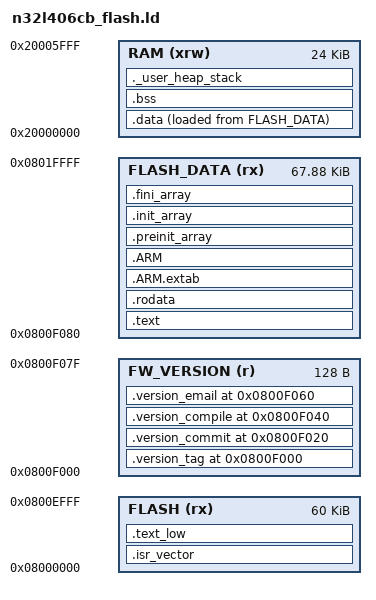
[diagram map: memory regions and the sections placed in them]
/**
  ****************************************************************************
  Copyright (c) 2019, Nations Technologies Inc.

  All rights reserved.
  ****************************************************************************

  Redistribution and use in source and binary forms, with or without
  modification, are permitted provided that the following conditions are met:

  - Redistributions of source code must retain the above copyright notice,
  this list of conditions and the disclaimer below.

  Nations' name may not be used to endorse or promote products derived from
  this software without specific prior written permission.

  DISCLAIMER: THIS SOFTWARE IS PROVIDED BY NATIONS "AS IS" AND ANY EXPRESS OR
  IMPLIED WARRANTIES, INCLUDING, BUT NOT LIMITED TO, THE IMPLIED WARRANTIES OF
  MERCHANTABILITY, FITNESS FOR A PARTICULAR PURPOSE AND NON-INFRINGEMENT ARE
  DISCLAIMED. IN NO EVENT SHALL NATIONS BE LIABLE FOR ANY DIRECT, INDIRECT,
  INCIDENTAL, SPECIAL, EXEMPLARY, OR CONSEQUENTIAL DAMAGES (INCLUDING, BUT NOT
  LIMITED TO, PROCUREMENT OF SUBSTITUTE GOODS OR SERVICES; LOSS OF USE, DATA,
  OR PROFITS; OR BUSINESS INTERRUPTION) HOWEVER CAUSED AND ON ANY THEORY OF
  LIABILITY, WHETHER IN CONTRACT, STRICT LIABILITY, OR TORT (INCLUDING
  NEGLIGENCE OR OTHERWISE) ARISING IN ANY WAY OUT OF THE USE OF THIS SOFTWARE,
  EVEN IF ADVISED OF THE POSSIBILITY OF SUCH DAMAGE.
  ****************************************************************************
 **/

/* Entry Point */
ENTRY(Reset_Handler)


/* Generate a link error if heap and stack don't fit into RAM */
_Min_Heap_Size = 0x200;      /* required amount of heap  */
_Min_Stack_Size = 0x800; /* required amount of stack */

/* Specify the memory areas */
MEMORY
{
FLASH (rx)      : ORIGIN = 0x08000000, LENGTH = 60K
FW_VERSION (r) : ORIGIN = 0x0800F000, LENGTH = 128
FLASH_DATA (rx): ORIGIN = 0x0800F080, LENGTH = 0x10F80
RAM (xrw)      : ORIGIN = 0x20000000, LENGTH = 24K
}

_estack = ORIGIN(RAM) + LENGTH(RAM);

/* Define output sections */
SECTIONS
{
  /* The startup code goes first into FLASH */
  .isr_vector :
  {
    . = ALIGN(4);
    KEEP(*(.isr_vector)) /* Startup code */
    . = ALIGN(4);
  } >FLASH

  .text_low :
  {
    . = ALIGN(4);
    CMakeFiles/*(.text .text.*)
    App/*/CMakeFiles/*(.text .text.*)
    *libext_store.a:*(.text .text.*)
    *libscale_mass_mgnt.a:*(.text .text.*)
    . = ALIGN(4);
  } >FLASH

  /* The program code and other data goes into FLASH */
  .text :
  {
    . = ALIGN(4);
    *(.text)           /* .text sections (code) */
    *(.text*)          /* .text* sections (code) */
    *(.glue_7)         /* glue arm to thumb code */
    *(.glue_7t)        /* glue thumb to arm code */
    *(.eh_frame)

    KEEP (*(.init))
    KEEP (*(.fini))
	
	/* section information for finsh shell */
	. = ALIGN(4);
	__fsymtab_start = .;
	KEEP(*(FSymTab))
	__fsymtab_end = .;

	. = ALIGN(4);
	__vsymtab_start = .;
	KEEP(*(VSymTab))
	__vsymtab_end = .;

	/* section information for initial. */
	. = ALIGN(4);
	__rt_init_start = .;
	KEEP(*(SORT(.rti_fn*)))
	__rt_init_end = .;

    . = ALIGN(4);
    _etext = .;        /* define a global symbols at end of code */
  } >FLASH_DATA

  .version_tag 0x0800F000 :
  {
    KEEP(*(.ARM.__at_0x0800F000))
  } >FW_VERSION
  .version_commit 0x0800F020 :
  {
    KEEP(*(.ARM.__at_0x0800F020))
  } >FW_VERSION
  .version_compile 0x0800F040 :
  {
    KEEP(*(.ARM.__at_0x0800F040))
  } >FW_VERSION
  .version_email 0x0800F060 :
  {
    KEEP(*(.ARM.__at_0x0800F060))
  } >FW_VERSION

  ASSERT(SIZEOF(.version_tag) == 32, "TAG_VERSION must occupy 32 bytes")
  ASSERT(SIZEOF(.version_commit) == 32, "COMMIT_TIME must occupy 32 bytes")
  ASSERT(SIZEOF(.version_compile) == 32, "LAST_COMPILE_TIME must occupy 32 bytes")
  ASSERT(SIZEOF(.version_email) == 32, "LAST_COMPILE_EMAIL must occupy 32 bytes")

  /* Constant data goes into FLASH */
  .rodata :
  {
    . = ALIGN(4);
    *(.rodata)         /* .rodata sections (constants, strings, etc.) */
    *(.rodata*)        /* .rodata* sections (constants, strings, etc.) */
    . = ALIGN(4);
  } >FLASH_DATA

  .ARM.extab   : { *(.ARM.extab* .gnu.linkonce.armextab.*) } >FLASH_DATA
  .ARM : {
    __exidx_start = .;
    *(.ARM.exidx*)
    __exidx_end = .;
  } >FLASH_DATA

  .preinit_array     :
  {
    PROVIDE_HIDDEN (__preinit_array_start = .);
    KEEP (*(.preinit_array*))
    PROVIDE_HIDDEN (__preinit_array_end = .);
  } >FLASH_DATA
  .init_array :
  {
    PROVIDE_HIDDEN (__init_array_start = .);
    KEEP (*(SORT(.init_array.*)))
    KEEP (*(.init_array*))
    PROVIDE_HIDDEN (__init_array_end = .);
  } >FLASH_DATA
  .fini_array :
  {
    PROVIDE_HIDDEN (__fini_array_start = .);
    KEEP (*(SORT(.fini_array.*)))
    KEEP (*(.fini_array*))
    PROVIDE_HIDDEN (__fini_array_end = .);
  } >FLASH_DATA

  /* used by the startup to initialize data */
  _sidata = LOADADDR(.data);

  /* Initialized data sections goes into RAM, load LMA copy after code */
  .data : 
  {
    . = ALIGN(4);
    _sdata = .;        /* create a global symbol at data start */
    *(.data)           /* .data sections */
    *(.data*)          /* .data* sections */
    *(.RamFunc)
    *(.RamFunc.*)

    . = ALIGN(4);
    _edata = .;        /* define a global symbol at data end */
  } >RAM AT> FLASH_DATA
  
  /* Uninitialized data section */
  . = ALIGN(4);
  .bss :
  {
    /* This is used by the startup in order to initialize the .bss secion */
    _sbss = .;         /* define a global symbol at bss start */
    __bss_start__ = _sbss;
    *(.bss)
    *(.bss*)
    *(COMMON)

    . = ALIGN(4);
    _ebss = .;         /* define a global symbol at bss end */
    __bss_end__ = _ebss;
  } >RAM

  /* User_heap_stack section, used to check that there is enough RAM left */
  ._user_heap_stack :
  {
    . = ALIGN(4);
    PROVIDE ( end = . );
    PROVIDE ( _end = . );
    . = . + _Min_Heap_Size;
    . = . + _Min_Stack_Size;
    . = ALIGN(4);
  } >RAM

  

  /* Remove information from the standard libraries */

  .ARM.attributes 0 : { *(.ARM.attributes) }
}
